# K1921VG1T register map
Vendor: NIIET; Series: K1921VGx; File version: 2.8
CPU: other r0p1, little endian, MPU, FPU, 4 interrupt priority bits
Registers are 32-bit, read-write, reset 0x0 unless marked. A register's access mark holds for its fields unless they carry their own. Offsets are from the block's base; [hi:lo] are bit positions; lines under a group give offsets from that group; {n}, {i} and the like mark numbered series.

## WDT — Watchdog timer
Base 0x50006000
0x00 LOAD reset 0xFFFFFFFF — Watchdog Load Register
  [31:0] VAL — Begin value counter
0x04 VALUE ro reset 0xFFFFFFFF — Watchdog Value Register
  [31:0] VAL — Current value counter
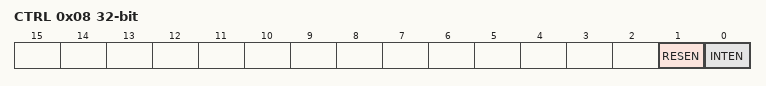
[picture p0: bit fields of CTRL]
0x08 CTRL — Watchdog Control Register
  [1] RESEN — Enable watchdog reset output
  [0] INTEN — Enable the interrupt event
0x0C INTCLR wo — Watchdog Clear Interrupt Register
  [0] WDTCLR — Reset interrupt WDT
0x10 RIS ro — Watchdog Raw Interrupt Status Register
  [0] RAWWDTINT — Raw interrupt status from the counter
0x14 MIS ro — Watchdog Interrupt Status Register
  [0] WDTINT — Enabled interrupt status from the counter
0xC00 LOCK wo — Watchdog Lock Register (write)
  [31:0] CODE — Enable write access to all other registers by writing LOCK = 0x1ACCE551. Disable write to any othr registers of Watchdog by writing any other value
    0x1ACCE551=UNLOCK (Value that clear LOCKSTAT.REGWRDIS bit); 0=LOCK_0 (Example value that set LOCKSTAT.REGWRDIS (write to all registers except LOCK is disabled)); 1=LOCK_1 (Example value that set LOCKSTAT.REGWRDIS (write to all registers except LOCK is disabled))
0xC00 LOCKSTAT ro (alternate view of LOCK) — Watchdog Lock Register (read)
  [0] REGWRDIS — Write to all registers of Watchdog is disabled

## SRAM — SRAM ECC control unit
Base 0x50007000
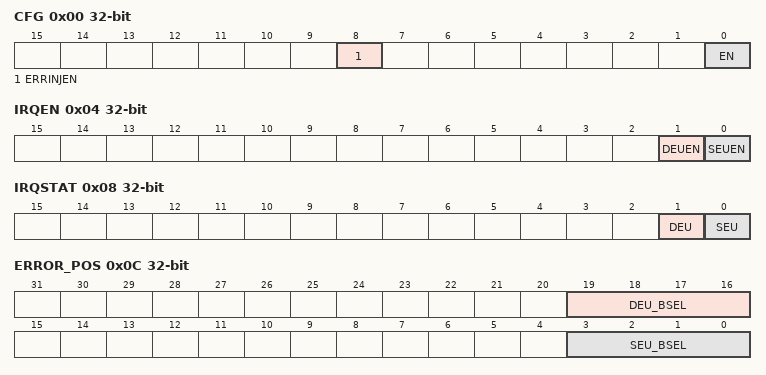
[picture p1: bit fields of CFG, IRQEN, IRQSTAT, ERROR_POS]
0x00 CFG — SRAM ECC Control register
  [8] ERRINJEN — Enable error injection on write data bus
  [0] EN — Enable ECC
0x04 IRQEN — SRAM ECC Interrupt Enable register
  [1] DEUEN — Enable interrupt when double errors detected
  [0] SEUEN — Enable interrupt when single error detected
0x08 IRQSTAT — SRAM ECC Interrupt Status register
  [1] DEU — Double error occurred
  [0] SEU — Single error occurred
0x0C ERROR_POS — SRAM Error Position in Byte register
  [19:16] DEU_BSEL — Byte position in a word in which double error has been occured
  [3:0] SEU_BSEL — Byte position in a word in which single error has been occured
0x10 SEU_CNTR — SRAM Single Error Counter register
  [31:0] VAL — Single error times occurred
0x14 DEU_CNTR — SRAM Double Error Counter register
  [31:0] VAL — Double error times occurred
0x18 SEU_ADDR — SRAM Single Error Address register
  [31:0] VAL — Last latched address when single error occurred
0x1C DEU_ADDR — SRAM Double Error Address register
  [31:0] VAL — Last latched address when double error occurred
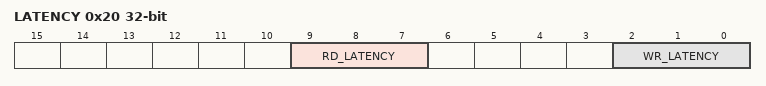
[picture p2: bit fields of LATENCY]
0x20 LATENCY — SRAM Read and Write Latency register
  [9:7] RD_LATENCY — SRAM Read Latency
  [2:0] WR_LATENCY — SRAM Write Latency
0x24 ERRMASK — SRAM Data Mask register
  [31:0] VAL — Corresponding bit of 32-bit write data bus is inverted

## EMC — External memory control module
Base 0x50009000
{0x0+4i} WINCFG[{i}] (i=0..7) group
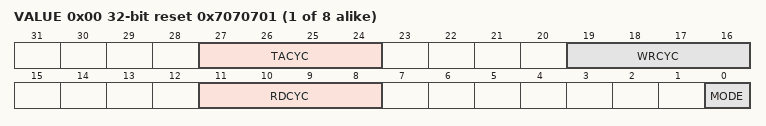
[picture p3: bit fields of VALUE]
  0x00 VALUE reset 0x7070701 — Window Configuration
    [27:24] TACYC — Turnaround cycles
    [19:16] WRCYC — Additional Write cycles
    [11:8] RDCYC — Additional Read cycles
    [0] MODE — 8/16 bit mode. When 1 - 16 bit mode enabled
      0=8 bit mode; 1=16 bit mode

## SDRAM — SDRAM controller unit
Base 0x5000A000
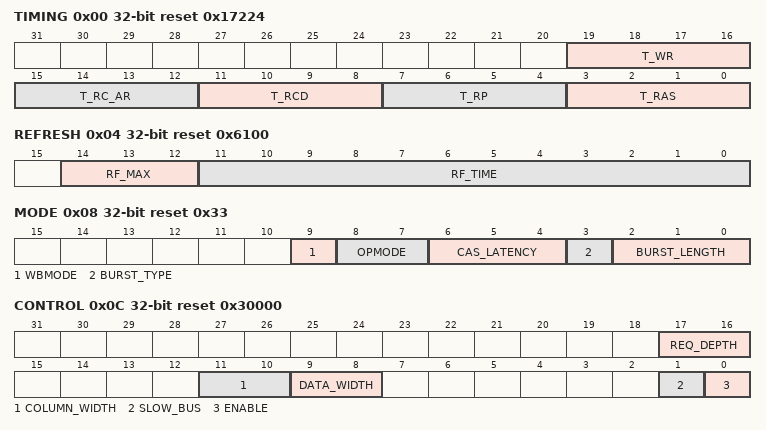
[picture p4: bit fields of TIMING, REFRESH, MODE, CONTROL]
0x00 TIMING reset 0x17224 — SDRAM Timing register
  [19:16] T_WR — SDRAM write recovery time, specified in clocks
  [15:12] T_RC_AR — SDRAM active to active/auto-refresh command period, specified in clocks
  [11:8] T_RCD — SDRAM active to read or write delay, specified in clocks
  [7:4] T_RP — SDRAM precharge command period, specified in clocks
  [3:0] T_RAS — SDRAM active to prechardge, specified in clocks
0x04 REFRESH reset 0x6100 — SDRAM Refresh register
  [14:12] RF_MAX — Maximum number of rows to be refreshed at a time
  [11:0] RF_TIME — Period between auto-refresh commands issued by the controller, specified in clocks
0x08 MODE reset 0x33 — SDRAM Mode register
  [9] WBMODE — Writing burst mode
    0=PBL (Programmed burst length); 1=SLA (Single location address)
  [8:7] OPMODE — Operating mode
    0=NORMAL (Normal operating mode); 1=RESERV1 (Reserved); 2=RESERV2 (Reserved); 3=RESERV3 (Reserved)
  [6:4] CAS_LATENCY — SDRAM CAS latency, specified in clocks
  [3] BURST_TYPE
    0=SEQUENTIAL (Sequential burst type); 1=INTERLEAVED (Interleaved burst type)
  [2:0] BURST_LENGTH
0x0C CONTROL reset 0x30000 — SDRAM Control register
  [17:16] REQ_DEPTH — How many requests internal buffer should hold
  [11:10] COLUMN_WIDTH — SDRAM Column Bit
    0=BIT8 (8 bit); 1=BIT9 (9 bit); 2=BIT10 (10 bits); 3=BIT11 (11 bits)
  [9:8] DATA_WIDTH — SDRAM Data Width
    0=DATA32 (32-bit SDRAM); 1=DATA16 (16-bit SDRAM); 2=DATA8 (8-bit SDRAM)
  [1] SLOW_BUS — Must be set if System clock frequency is less than SDRAM frequency
  [0] ENABLE — SDRAM Controller enable
0x10 STATUS ro — SDRAM Status register
  [0] INIT_DONE — Indicate that SDRAM Initialization has done
